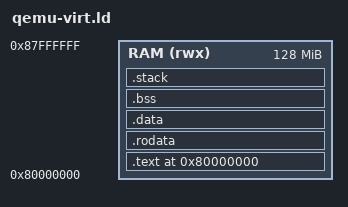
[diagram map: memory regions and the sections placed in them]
OUTPUT_ARCH(riscv)
ENTRY(_start)

MEMORY
{
    RAM (rwx) : ORIGIN = 0x80000000, LENGTH = 128M
}

SECTIONS
{
    . = ORIGIN(RAM);
    __image_start = .;

    .text : ALIGN(4096)
    {
        KEEP(*(.text.init))
        *(.text .text.*)
    } > RAM

    .rodata : ALIGN(16)
    {
        *(.srodata .srodata.*)
        *(.rodata .rodata.*)
    } > RAM

    .data : ALIGN(16)
    {
        PROVIDE(__global_pointer$ = . + 0x800);
        *(.sdata .sdata.*)
        *(.data .data.*)
    } > RAM

    .bss (NOLOAD) : ALIGN(16)
    {
        __bss_start = .;
        *(.bss .bss.*)
        *(COMMON)
        __bss_end = .;
    } > RAM

    .stack (NOLOAD) : ALIGN(16)
    {
        __stack_bottom = .;
        . += 64K;
        __stack_top = .;
    } > RAM

    __image_end = .;

    /DISCARD/ :
    {
        *(.comment)
        *(.eh_frame .eh_frame.*)
        *(.note .note.*)
    }
}
